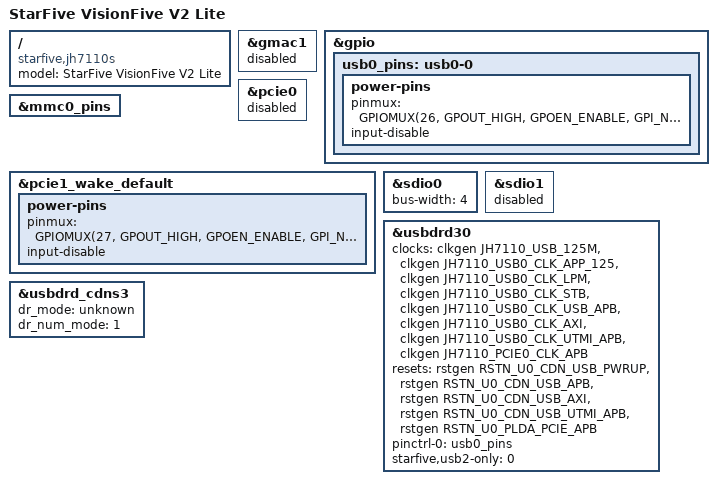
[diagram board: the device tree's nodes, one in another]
// SPDX-License-Identifier: GPL-2.0 OR MIT
/*
 * Copyright (C) 2025 StarFive Technology Co., Ltd.
 * Copyright (C) 2025 Hal Feng <hal.feng@starfivetech.com>
 */

/dts-v1/;

#include "starfive_visionfive2.dts"
/ {
	#address-cells = <2>;
	#size-cells = <2>;
	model = "StarFive VisionFive V2 Lite";
	compatible = "starfive,jh7110s";
};

&gmac1 {
	status = "disabled";
};

&gpio {
	usb0_pins: usb0-0 {
		power-pins {
			pinmux = <GPIOMUX(26, GPOUT_HIGH,
					      GPOEN_ENABLE,
					      GPI_NONE)>;
			input-disable;
		};
	};
};

&mmc0_pins {
	/delete-node/ mmc0-pins-rest;
};

&pcie0 {
	status = "disabled";
};

&pcie1_wake_default {
	power-pins {
		pinmux = <GPIOMUX(27, GPOUT_HIGH,
				      GPOEN_ENABLE,
				      GPI_NONE)>;
		input-disable;
	};
};

&sdio0 {
	bus-width = <4>;
};

&sdio1 {
	status = "disabled";
};

&usbdrd30 {
	clocks = <&clkgen JH7110_USB_125M>,
		 <&clkgen JH7110_USB0_CLK_APP_125>,
		 <&clkgen JH7110_USB0_CLK_LPM>,
		 <&clkgen JH7110_USB0_CLK_STB>,
		 <&clkgen JH7110_USB0_CLK_USB_APB>,
		 <&clkgen JH7110_USB0_CLK_AXI>,
		 <&clkgen JH7110_USB0_CLK_UTMI_APB>,
		 <&clkgen JH7110_PCIE0_CLK_APB>;
	clock-names = "125m","app","lpm","stb","apb","axi","utmi", "phy";
	resets = <&rstgen RSTN_U0_CDN_USB_PWRUP>,
		 <&rstgen RSTN_U0_CDN_USB_APB>,
		 <&rstgen RSTN_U0_CDN_USB_AXI>,
		 <&rstgen RSTN_U0_CDN_USB_UTMI_APB>,
		 <&rstgen RSTN_U0_PLDA_PCIE_APB>;
	reset-names = "pwrup","apb","axi","utmi", "phy";
	pinctrl-names = "default";
	pinctrl-0 = <&usb0_pins>;
	starfive,usb2-only = <0>;
};

&usbdrd_cdns3 {
	dr_mode = "unknown";
	dr_num_mode = <1>;
};
